# STM32N647 register map
File version: 1.0
CPU: CM55 r0p1, little endian, no MPU, FPU, vendor SysTick, 8 interrupt priority bits
Registers are 32-bit, read-write, reset 0x0 unless marked. A register's access mark holds for its fields unless they carry their own. Offsets are from the block's base; [hi:lo] are bit positions; {n}, {i} and the like mark numbered series.

## MDF1 — MDF register block
Base 0x42025000
Same registers: MDF1_S 0x52025000
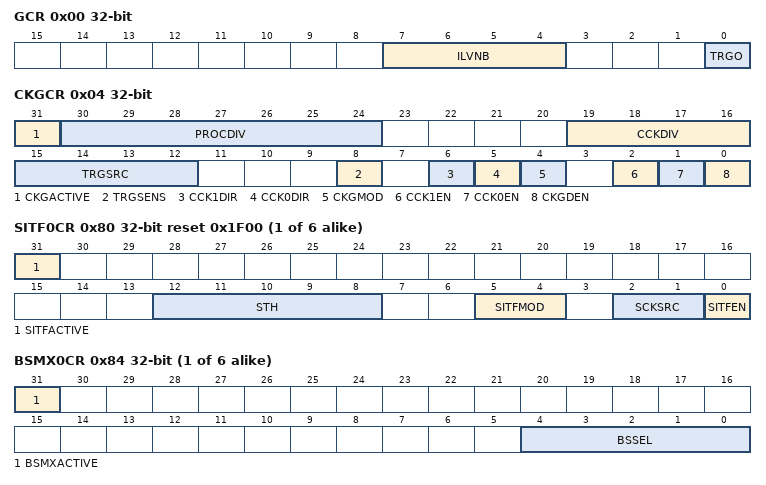
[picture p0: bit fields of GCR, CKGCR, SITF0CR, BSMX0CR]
0x00 GCR — MDF global control register
  [7:4] ILVNB — Interleaved number
  [0] TRGO — Trigger output control
0x04 CKGCR access per field — MDF clock generator control register
  [31] CKGACTIVE ro — Clock generator active flag
  [30:24] PROCDIV rw — Divider to control the serial interface clock
  [19:16] CCKDIV rw — Divider to control the MDF_CCK clock
  [15:12] TRGSRC rw — Digital filter trigger signal selection
  [8] TRGSENS rw — CKGEN trigger sensitivity selection
  [6] CCK1DIR rw — MDF_CCK1 direction
  [5] CCK0DIR rw — MDF_CCK0 direction
  [4] CKGMOD rw — Clock generator mode
  [2] CCK1EN rw — MDF_CCK1 clock enable
  [1] CCK0EN rw — MDF_CCK0 clock enable
  [0] CKGDEN rw — CKGEN dividers enable
{0x80+0x80*i} SITF{i}CR access per field reset 0x1F00 (i=0..5) — MDF serial interface control register {i}
  [31] SITFACTIVE ro — Serial interface active flag
  [12:8] STH rw — Manchester symbol threshold/SPI threshold
  [5:4] SITFMOD rw — Serial interface type
  [2:1] SCKSRC rw — Serial clock source
  [0] SITFEN rw — Serial interface enable
{0x84+0x80*i} BSMX{i}CR access per field (i=0..5) — MDF bitstream matrix control register {i}
  [31] BSMXACTIVE ro — BSMX active flag
  [4:0] BSSEL rw — Bitstream Selection
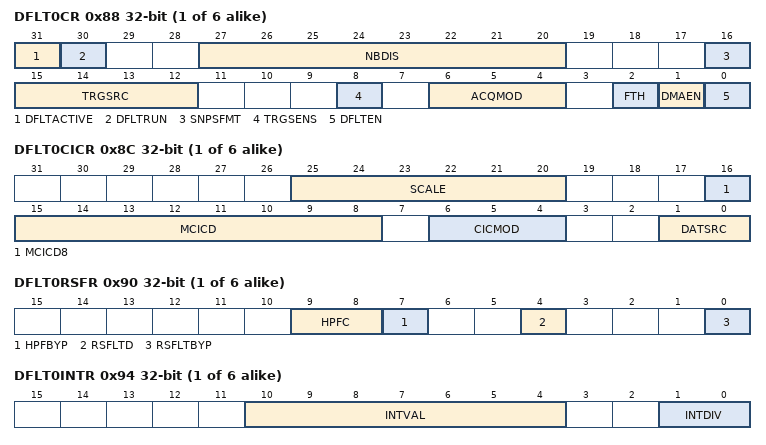
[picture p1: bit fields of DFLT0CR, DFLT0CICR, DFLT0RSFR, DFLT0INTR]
{0x88+0x80*i} DFLT{i}CR access per field (i=0..5) — MDF digital filter control register {i}
  [31] DFLTACTIVE ro — Digital filter active flag
  [30] DFLTRUN ro — Digital filter run status flag
  [27:20] NBDIS rw — Number of samples to be discarded
  [16] SNPSFMT rw — Snapshot data format
  [15:12] TRGSRC rw — Digital filter trigger signal selection
  [8] TRGSENS rw — Digital filter trigger sensitivity selection
  [6:4] ACQMOD rw — Digital filter trigger mode
  [2] FTH rw — RXFIFO Threshold selection
  [1] DMAEN rw — DMA requests enable
  [0] DFLTEN wo — Digital filter enable
{0x8C+0x80*i} DFLT{i}CICR (i=0..5) — MDF digital filter configuration register {i}
  [25:20] SCALE — Scaling factor selection
  [16] MCICD8 — CIC decimation ratio selection
  [15:8] MCICD — CIC decimation ratio selection
  [6:4] CICMOD — Select the CIC mode
  [1:0] DATSRC — Source data for the digital filter
{0x90+0x80*i} DFLT{i}RSFR (i=0..5) — MDF reshape filter configuration register {i}
  [9:8] HPFC — High-pass filter cut-off frequency
  [7] HPFBYP — High-pass filter bypass
  [4] RSFLTD — Reshaper filter decimation ratio
  [0] RSFLTBYP — Reshaper filter bypass
{0x94+0x80*i} DFLT{i}INTR (i=0..5) — MDF integrator configuration register {i}
  [10:4] INTVAL — Integration value selection
  [1:0] INTDIV — Integrator output division
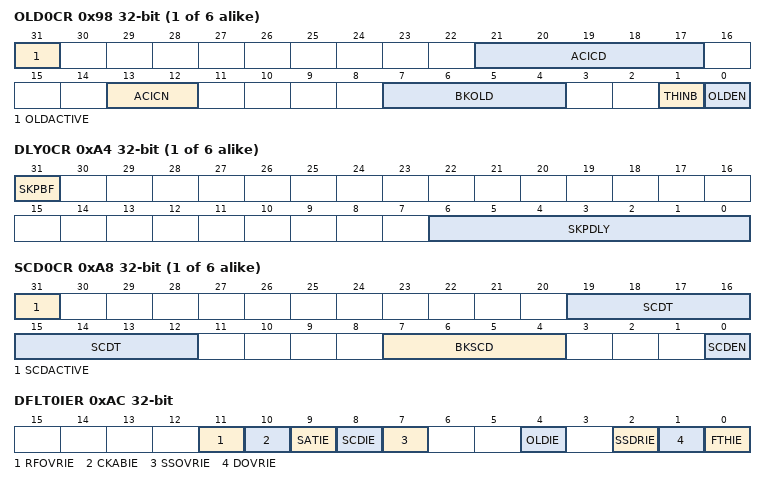
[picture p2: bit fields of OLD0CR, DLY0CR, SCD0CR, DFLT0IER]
{0x98+0x80*i} OLD{i}CR access per field (i=0..5) — MDF out-of limit detector control register {i}
  [31] OLDACTIVE ro — OLDx active flag
  [21:17] ACICD rw — OLDx CIC decimation ratio selection
  [13:12] ACICN rw — OLDx CIC order selection
  [7:4] BKOLD rw — Break signal assignment for out-of limit detector
  [1] THINB rw — Threshold In band
  [0] OLDEN rw — OLDx enable
{0x9C+0x80*i} OLD{i}THLR (i=0..5) — MDF OLD{i} low threshold register {i}
  [25:0] OLDTHL — OLD low threshold value
{0xA0+0x80*i} OLD{i}THHR (i=0..5) — MDF OLD{i} high threshold register {i}
  [25:0] OLDTHH — OLDx high threshold value
{0xA4+0x80*i} DLY{i}CR access per field (i=0..5) — MDF delay control register {i}
  [31] SKPBF ro — Skip busy flag
  [6:0] SKPDLY rw — Delay to apply to a bitstream
{0xA8+0x80*i} SCD{i}CR access per field (i=0..5) — MDF short circuit detector control register {i}
  [31] SCDACTIVE ro — SCDx active flag
  [19:12] SCDT rw — SCDx threshold
  [7:4] BKSCD rw — Break signal assignment for short circuit detector
  [0] SCDEN rw — SCDx enable
0xAC DFLT0IER — MDF DFLT0 interrupt enable register 0
  [11] RFOVRIE — Reshape filter overrun interrupt enable
  [10] CKABIE — Clock absence detection interrupt enable
  [9] SATIE — Saturation detection interrupt enable
  [8] SCDIE — SCD0 interrupt enable
  [7] SSOVRIE — Snapshot overrun interrupt enable
  [4] OLDIE — OLD0 interrupt enable
  [2] SSDRIE — Snapshot data ready interrupt enable
  [1] DOVRIE — Data overflow interrupt enable
  [0] FTHIE — RXFIFO threshold interrupt enable
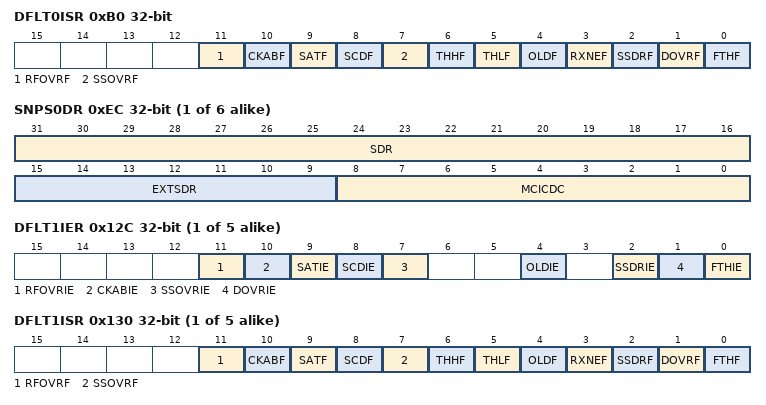
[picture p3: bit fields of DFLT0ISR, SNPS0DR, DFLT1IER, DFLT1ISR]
0xB0 DFLT0ISR access per field — MDF DFLT0 interrupt status register 0
  [11] RFOVRF rw — Reshape filter overrun detection flag
  [10] CKABF rw — Clock absence detection flag
  [9] SATF rw — Saturation detection flag
  [8] SCDF rw — Short-circuit detector flag
  [7] SSOVRF rw — Snapshot overrun flag
  [6] THHF ro — High-threshold status flag
  [5] THLF ro — Low-threshold status flag
  [4] OLDF rw — OLD0 flag
  [3] RXNEF ro — RXFIFO not-empty flag
  [2] SSDRF rw — Snapshot data ready flag
  [1] DOVRF rw — Data overflow flag
  [0] FTHF ro — RXFIFO threshold flag
{0xB4+0x80*i} OEC{i}CR (i=0..5) — MDF offset error compensation control register {i}
  [25:0] OFFSET — Offset error compensation
{0xEC+0x80*i} SNPS{i}DR ro (i=0..5) — MDF snapshot data register {i}
  [31:16] SDR — Contains the 16 MSB of the last valid data processed by the digital filter.
  [15:9] EXTSDR — Extended data size
  [8:0] MCICDC — Contains the MCIC decimation counter value when the last trigger event occurs (MCIC_CNT)
{0xF0+0x80*i} DFLT{i}DR ro (i=0..5) — MDF digital filter data register {i}
  [31:8] DR — Data processed by digital filter
{0xAC+0x80*i} DFLT{i}IER (i=1..5) — MDF DFLT{i} interrupt enable register {i}
  [11] RFOVRIE — Reshape filter overrun interrupt enable
  [10] CKABIE — Clock absence detection interrupt enable
  [9] SATIE — Saturation detection interrupt enable
  [8] SCDIE — SCDx interrupt enable
  [7] SSOVRIE — Snapshot overrun interrupt enable
  [4] OLDIE — OLDx interrupt enable
  [2] SSDRIE — Snapshot data ready interrupt enable
  [1] DOVRIE — Data overflow interrupt enable
  [0] FTHIE — RXFIFO threshold interrupt enable
{0xB0+0x80*i} DFLT{i}ISR access per field (i=1..5) — MDF DFLT{i} interrupt status register {i}
  [11] RFOVRF rw — Reshape filter overrun detection flag
  [10] CKABF rw — Clock absence detection flag
  [9] SATF rw — Saturation detection flag
  [8] SCDF rw — Short-circuit detector flag
  [7] SSOVRF rw — Snapshot overrun flag
  [6] THHF ro — High-threshold status flag
  [5] THLF ro — Low-threshold status flag
  [4] OLDF rw — OLDx flag
  [3] RXNEF ro — RXFIFO not-empty flag
  [2] SSDRF rw — Snapshot data ready flag
  [1] DOVRF rw — Data overflow flag
  [0] FTHF ro — RXFIFO threshold flag
